# TLE984x register map
Vendor: Infineon Technologies AG; File version: 1.6
CPU: CM0 r0p0, little endian, no MPU, no FPU, 2 interrupt priority bits
Registers are 32-bit, read-write, no defined reset value unless marked. A register's access mark holds for its fields unless they carry their own. Offsets are from the block's base; [hi:lo] are bit positions; {n}, {i} and the like mark numbered series; 'fields as' and 'values as' point back to an identical list.

## PORT
Base 0x48028000
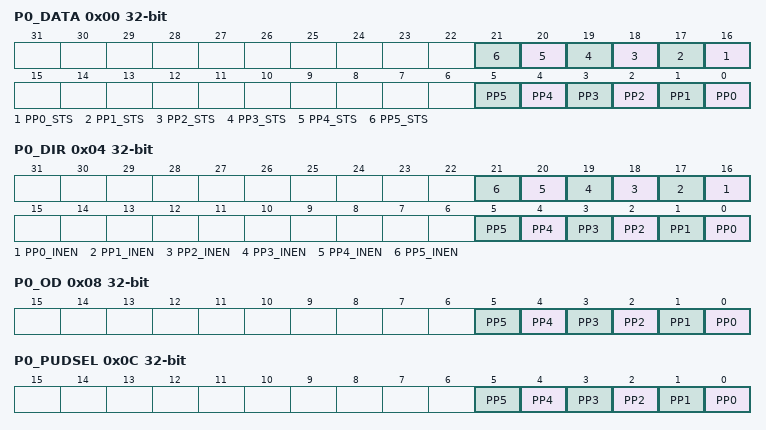
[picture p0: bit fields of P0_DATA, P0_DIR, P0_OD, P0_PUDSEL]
0x00 P0_DATA access per field — Port 0 Data Register
  [n+16] PP{n}_STS ro (n=0..5) — Port 0 Pin {n} Data Value (read back of Port Data when IO is configured as output)
    0=Port 0 pin {n} data value = 0; 1=Port 0 pin {n} data value = 1
  [n] PP{n} rw (n=0..5) — Port 0 Pin {n} Data Value
    values as PP0_STS
0x04 P0_DIR — Port 0 Direction Register
  [n+16] PP{n}_INEN (n=0..5) — Port 0 Pin {n} Input Schmitt Trigger enable (only valid if IO is configured as output)
    0=Schmitt Trigger is disabled (default); 1=Schmitt Trigger is enabled
  [n] PP{n} (n=0..5) — Port 0 Pin {n} Direction Control
    0=Direction is set to input (default); 1=Direction is set to output
0x08 P0_OD — Port 0 Open Drain Control Register
  [all] fields
    0=Normal Mode (Output is actively driven for 0 and 1 state (default)); 1=Open Drain Mode (Output is actively driven only for 0 state)
  [n] PP{n} (n=0..5) — Port 0 Pin {n} Open Drain Mode
0x0C P0_PUDSEL — Port 0 Pull-Up/Pull-Down Select Register
  [all] fields
    0=Pull-down device is selected; 1=Pull-up device is selected (default)
  [n] PP{n} (n=0..5) — Pull-Up/Pull-Down Select Port 0 Bit {n}
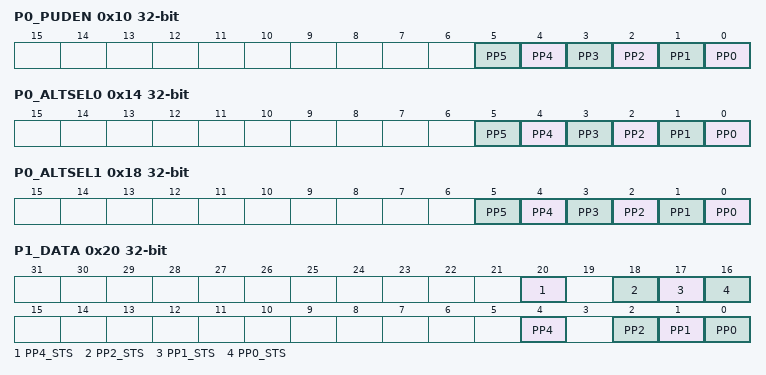
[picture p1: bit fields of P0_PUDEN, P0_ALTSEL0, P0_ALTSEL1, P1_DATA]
0x10 P0_PUDEN — Port 0 Pull-Up/Pull-Down Enable Register
  [all] fields
    0=Disabled (Pull-up or Pull-down device is disabled); 1=Enabled (Pull-up or Pull-down device is enabled (default))
  [n] PP{n} (n=0..5) — Pull-Up/Pull-Down Enable at Port 0 Bit {n}
0x14 P0_ALTSEL0 — Port 0 Alternate Select Register 0
  [n] PP{n} (n=0..5) — See
0x18 P0_ALTSEL1 — Port 0 Alternate Select Register 1
  [n] PP{n} (n=0..5) — See
0x20 P1_DATA — Port 1 Data Register
  [20] PP4_STS — Port 1 Pin 4 Data Value (read back of Port Data when IO is configured as output)
    0=Port 1 pin 4 data value = 0; 1=Port 1 pin 4 data value = 1
  [18] PP2_STS — Port 1 Pin 2 Data Value (read back of Port Data when IO is configured as output)
    0=Port 1 pin 2 data value = 0; 1=Port 1 pin 2 data value = 1
  [17] PP1_STS — Port 1 Pin 1 Data Value (read back of Port Data when IO is configured as output)
    0=Port 1 pin 1 data value = 0; 1=Port 1 pin 1 data value = 1
  [16] PP0_STS — Port 1 Pin 0 Data Value (read back of Port Data when IO is configured as output)
    0=Port 1 pin 0 data value = 0; 1=Port 1 pin 0 data value = 1
  [4] PP4 — Port 1 Pin 4 Data Value
    0=Port 1 pin 4 data value = 0; 1=Port 1 pin 4 data value = 1
  [2] PP2 — Port 1 Pin 2 Data Value
    0=Port 1 pin 2 data value = 0; 1=Port 1 pin 2 data value = 1
  [1] PP1 — Port 1 Pin 1 Data Value
    0=Port 1 pin 1 data value = 0; 1=Port 1 pin 1 data value = 1
  [0] PP0 — Port 1 Pin 0 Data Value
    0=Port 1 pin 0 data value = 0; 1=Port 1 pin 0 data value = 1
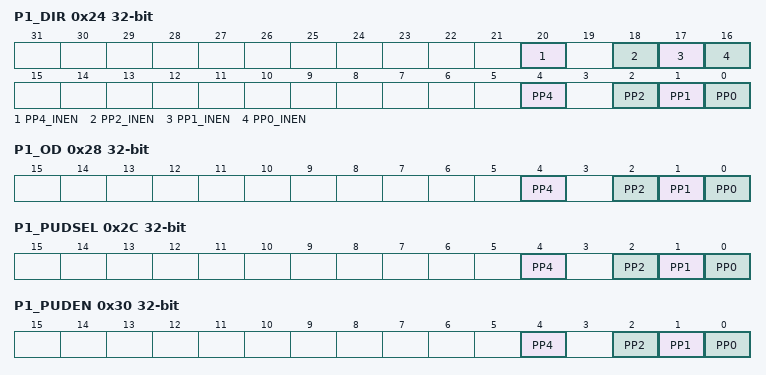
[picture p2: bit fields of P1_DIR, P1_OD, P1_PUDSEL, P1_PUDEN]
0x24 P1_DIR — Port 1 Direction Register
  [20] PP4_INEN — Port 1 Pin 4 Input Schmitt Trigger enable (only valid if IO is configured as output)
    values as P0_DIR.PP0_INEN
  [18] PP2_INEN — Port 1 Pin 2 Input Schmitt Trigger enable (only valid if IO is configured as output)
    values as P0_DIR.PP0_INEN
  [17] PP1_INEN — Port 1 Pin 1 Input Schmitt Trigger enable (only valid if IO is configured as output)
    values as P0_DIR.PP0_INEN
  [16] PP0_INEN — Port 1 Pin 0 Input Schmitt Trigger enable (only valid if IO is configured as output)
    values as P0_DIR.PP0_INEN
  [4] PP4 — Port 1 Pin 4 Direction Control
    0=Input (Direction is set to input (default)); 1=Output (Direction is set to output)
  [2] PP2 — Port 1 Pin 2 Direction Control
    values as PP4
  [1] PP1 — Port 1 Pin 1 Direction Control
    values as PP4
  [0] PP0 — Port 1 Pin 0 Direction Control
    values as PP4
0x28 P1_OD — Port 1 Open Drain Control Register
  [all] fields
    values as the fields of P0_OD
  [4] PP4 — Port 1 Pin 4 Open Drain Mode
  [2] PP2 — Port 1 Pin 2 Open Drain Mode
  [1] PP1 — Port 1 Pin 1 Open Drain Mode
  [0] PP0 — Port 1 Pin 0 Open Drain Mode
0x2C P1_PUDSEL — Port 1 Pull-Up/Pull-Down Select Register
  [all] fields
    values as the fields of P0_PUDSEL
  [4] PP4 — Pull-Up/Pull-Down Select Port 1 Bit 4
  [2] PP2 — Pull-Up/Pull-Down Select Port 1 Bit 2
  [1] PP1 — Pull-Up/Pull-Down Select Port 1 Bit 1
  [0] PP0 — Pull-Up/Pull-Down Select Port 1 Bit 0
0x30 P1_PUDEN — Port 1 Pull-Up/Pull-Down Enable Register
  [all] fields
    0=Disabled (Pull-up or Pull-down device is disabled (default)); 1=Enabled (Pull-up or Pull-down device is enabled)
  [4] PP4 — Pull-Up/Pull-Down Enable at Port 1 Bit 4
  [2] PP2 — Pull-Up/Pull-Down Enable at Port 1 Bit 2
  [1] PP1 — Pull-Up/Pull-Down Enable at Port 1 Bit 1
  [0] PP0 — Pull-Up/Pull-Down Enable at Port 1 Bit 0
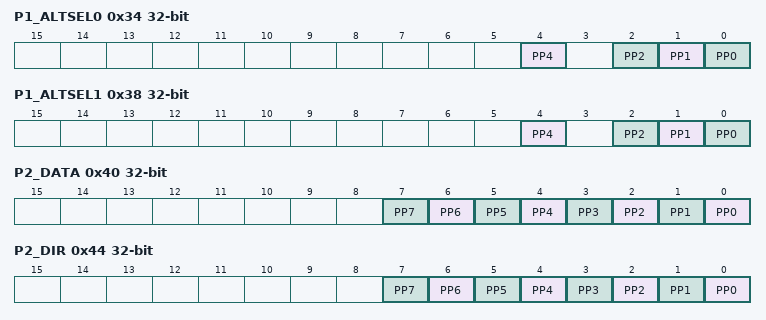
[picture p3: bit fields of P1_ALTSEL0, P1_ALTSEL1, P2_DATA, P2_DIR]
0x34 P1_ALTSEL0 — Port 1 Alternate Select Register 0
  [4] PP4 — See
  [2] PP2 — See
  [1] PP1 — See
  [0] PP0 — See
0x38 P1_ALTSEL1 — Port 1 Alternate Select Register 1
  [4] PP4 — See
  [2] PP2 — See
  [1] PP1 — See
  [0] PP0 — See
0x40 P2_DATA — Port 2 Data Register
  [n] PP{n} (n=0..7) — Port 2 Pin {n} Data Value
    0=Port 2 pin {n} data value = 0; 1=Port 2 pin {n} data value = 1
0x44 P2_DIR — Port 2 Direction Register
  [all] fields
    0=Enabled (Input driver is enabled (default)); 1=Disabled (Input driver is disabled)
  [n] PP{n} (n=0..7) — Port 2 Pin {n} Driver Control
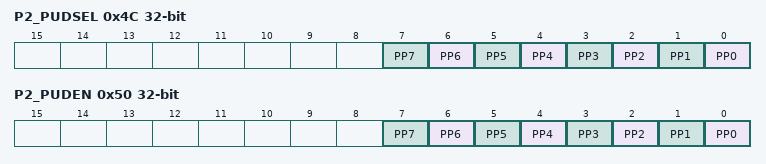
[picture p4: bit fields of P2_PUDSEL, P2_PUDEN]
0x4C P2_PUDSEL — Port 2 Pull-Up/Pull-Down Select Register
  [all] fields
    0=Pull-down device is selected (default); 1=Pull-up device is selected
  [n] PP{n} (n=0..7) — Pull-Up/Pull-Down Select Port 2 Bit {n}
0x50 P2_PUDEN — Port 2 Pull-Up/Pull-Down Enable Register
  [all] fields
    values as the fields of P1_PUDEN
  [n] PP{n} (n=0..7) — Pull-Up/Pull-Down Enable at Port 2 Bit {n}
